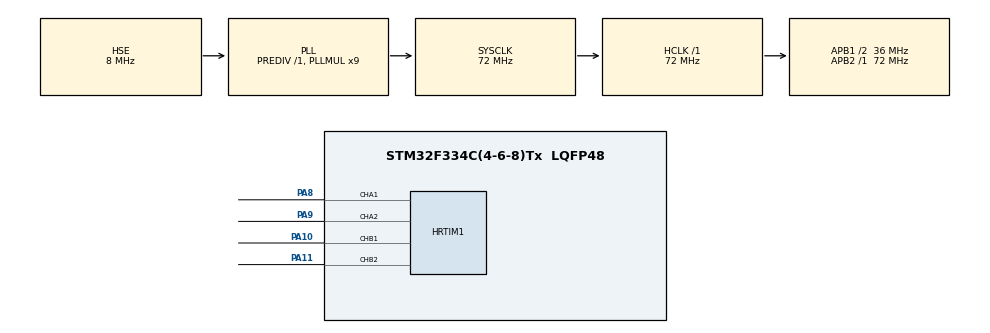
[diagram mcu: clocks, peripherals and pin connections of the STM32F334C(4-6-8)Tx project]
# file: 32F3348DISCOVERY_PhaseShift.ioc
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HRTIM1.CompareUnit1-MasterTimer=HRTIM_COMPAREUNIT_1
HRTIM1.CompareUnit1-Output_TA1TA2=HRTIM_COMPAREUNIT_1
HRTIM1.CompareUnit1-Output_TB1TB2=HRTIM_COMPAREUNIT_1
HRTIM1.CompareUnit2-MasterTimer=__NULL
HRTIM1.CompareUnit2-Output_TA1TA2=__NULL
HRTIM1.CompareUnit2-Output_TB1TB2=__NULL
HRTIM1.CompareUnit3-MasterTimer=__NULL
HRTIM1.CompareUnit4-MasterTimer=__NULL
HRTIM1.CompareValue1-MasterTimer=2880
HRTIM1.CompareValue2-MasterTimer=0xA000/5*2
HRTIM1.CompareValue3-MasterTimer=0xA000/5*3
HRTIM1.CompareValue4-MasterTimer=0xA000/5*4
HRTIM1.DeadTimeInsertion-Output_TA1TA2=HRTIM_TIMDEADTIMEINSERTION_ENABLED
HRTIM1.DeadTimeInsertion-Output_TB1TB2=HRTIM_TIMDEADTIMEINSERTION_ENABLED
HRTIM1.FallingValue-Output_TA1TA2=300
HRTIM1.FallingValue-Output_TB1TB2=300
HRTIM1.HalfModeEnable-Output_TA1TA2=HRTIM_HALFMODE_ENABLED
HRTIM1.HalfModeEnable-Output_TB1TB2=HRTIM_HALFMODE_ENABLED
HRTIM1.InterruptRequests1_Master=HRTIM_MASTER_IT_MREP
HRTIM1.ModeTimeBase-Output_TA1TA2=HRTIM_MODE_SINGLESHOT_RETRIGGERABLE
HRTIM1.ModeTimeBase-Output_TB1TB2=HRTIM_MODE_SINGLESHOT_RETRIGGERABLE
HRTIM1.NumberInterruptRequests_Master-MasterTimer=0
HRTIM1.NumberResetSource1-Output_TA1TA2=1
HRTIM1.NumberResetSource1-Output_TB1TB2=1
HRTIM1.NumberResetTrigger-Output_TA1TA2=1
HRTIM1.NumberResetTrigger-Output_TB1TB2=1
HRTIM1.NumberSetSource1-Output_TA1TA2=1
HRTIM1.NumberSetSource1-Output_TB1TB2=1
HRTIM1.NumberUpdateTrigger-Output_TA1TA2=0
HRTIM1.NumberUpdateTrigger-Output_TB1TB2=0
HRTIM1.Periode_MASTER=28800
HRTIM1.Periode_TA=28800
HRTIM1.Periode_TB=28800
HRTIM1.PreloadEnable-MasterTimer=HRTIM_PRELOAD_ENABLED
HRTIM1.PreloadEnable-Output_TA1TA2=HRTIM_PRELOAD_ENABLED
HRTIM1.PrescalerRatio_MASTER=HRTIM_PRESCALERRATIO_MUL16
HRTIM1.PrescalerRatio_TA=HRTIM_PRESCALERRATIO_MUL16
HRTIM1.PrescalerRatio_TB=HRTIM_PRESCALERRATIO_MUL16
HRTIM1.RepetitionCounter-MasterTimer=0
HRTIM1.RepetitionCounter-Output_TA1TA2=0
HRTIM1.RepetitionUpdate-MasterTimer=HRTIM_UPDATEONREPETITION_ENABLED
HRTIM1.RepetitionUpdate-Output_TA1TA2=HRTIM_UPDATEONREPETITION_DISABLED
HRTIM1.RepetitionUpdate-Output_TB1TB2=HRTIM_UPDATEONREPETITION_DISABLED
HRTIM1.ResetOutput1_Source1-Output_TA1TA2=HRTIM_OUTPUTRESET_TIMCMP1
HRTIM1.ResetOutput1_Source1-Output_TB1TB2=HRTIM_OUTPUTRESET_TIMCMP1
HRTIM1.ResetTrigger1-Output_TA1TA2=HRTIM_TIMRESETTRIGGER_MASTER_PER
HRTIM1.ResetTrigger1-Output_TB1TB2=HRTIM_TIMRESETTRIGGER_MASTER_CMP1
HRTIM1.ResetUpdate-Output_TA1TA2=HRTIM_TIMUPDATEONRESET_ENABLED
HRTIM1.ResetUpdate-Output_TB1TB2=HRTIM_TIMUPDATEONRESET_ENABLED
HRTIM1.RisingValue-Output_TA1TA2=300
HRTIM1.RisingValue-Output_TB1TB2=300
HRTIM1.SetOutput1_Source1-Output_TA1TA2=HRTIM_OUTPUTSET_TIMPER
HRTIM1.SetOutput1_Source1-Output_TB1TB2=HRTIM_OUTPUTSET_MASTERCMP1
HRTIM1.UpdateTrigger1-Output_TA1TA2=HRTIM_TIMUPDATETRIGGER_MASTER
HRTIM1.UpdateTrigger1-Output_TB1TB2=HRTIM_TIMUPDATETRIGGER_MASTER
Mcu.Family=STM32F3
Mcu.Name=STM32F334C(4-6-8)Tx
Mcu.Package=LQFP48
NVIC.PriorityGroup=NVIC_PRIORITYGROUP_0
PA10.Mode=Output_TB1TB2
PA10.Signal=HRTIM1_CHB1
PA11.Mode=Output_TB1TB2
PA11.Signal=HRTIM1_CHB2
PA13.Mode=Serial_Wire
PA13.Signal=SYS_JTMS-SWDIO
PA14.Mode=Serial_Wire
PA14.Signal=SYS_JTCK-SWCLK
PA8.Mode=Output_TA1TA2
PA8.Signal=HRTIM1_CHA1
PA9.Mode=Output_TA1TA2
PA9.Signal=HRTIM1_CHA2
PF0\ /\ OSC_IN.Mode=HSE-External-Clock-Source
PF0\ /\ OSC_IN.Signal=RCC_OSC_IN
ProjectManager.HeapSize=0x200
ProjectManager.StackSize=0x400
ProjectManager.TargetToolchain=STM32CubeIDE
RCC.AHBFreq_Value=72000000
RCC.APB1CLKDivider=RCC_HCLK_DIV2
RCC.APB1Freq_Value=36000000
RCC.APB1TimFreq_Value=72000000
RCC.APB2Freq_Value=72000000
RCC.APB2TimFreq_Value=72000000
RCC.CortexFreq_Value=72000000
RCC.HCLKFreq_Value=72000000
RCC.HRTIMSelection=RCC_HRTIM1CLK_PLLCLK
RCC.HSE_VALUE=8000000
RCC.HSI_VALUE=8000000
RCC.LSE_VALUE=32768
RCC.PLLMUL=RCC_PLL_MUL9
RCC.PLLSourceVirtual=RCC_PLLSOURCE_HSE
RCC.SYSCLKFreq_VALUE=72000000
RCC.SYSCLKSourceVirtual=RCC_SYSCLKSOURCE_PLLCLK
VP_HRTIM1_VS_hrtimMasterTimerNoOutput.Mode=MasterTimer
board=STM32F3348-DISCO

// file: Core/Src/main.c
/* USER CODE BEGIN Header */
/**
  ******************************************************************************
  * @file           : main.c
  * @brief          : Main program body
  ******************************************************************************
  * @attention
  *
  * <h2><center>&copy; Copyright (c) 2019 STMicroelectronics.
  * All rights reserved.</center></h2>
  *
  * This software component is licensed by ST under BSD 3-Clause license,
  * the "License"; You may not use this file except in compliance with the
  * License. You may obtain a copy of the License at:
  *                        opensource.org/licenses/BSD-3-Clause
  *
  ******************************************************************************
  */
/* USER CODE END Header */

#include "main.h"

HRTIM_HandleTypeDef hhrtim1;

void SystemClock_Config(void);
static void MX_GPIO_Init(void);
static void MX_HRTIM1_Init(void);
/* USER CODE BEGIN PFP */

static void HRTIM1_Start_Output(void);

/* USER CODE END PFP */

int main(void)
{

  /* MCU Configuration--------------------------------------------------------*/

  /* Reset of all peripherals, Initializes the Flash interface and the Systick. */
  HAL_Init();

  /* Configure the system clock */
  SystemClock_Config();

  /* Initialize all configured peripherals */
  MX_GPIO_Init();
  MX_HRTIM1_Init();
  /* USER CODE BEGIN 2 */

  HRTIM1_Start_Output();

  /* USER CODE END 2 */

  /* Infinite loop */
  while (1)
  {

  }
}

void SystemClock_Config(void)
{
  RCC_OscInitTypeDef RCC_OscInitStruct = {0};
  RCC_ClkInitTypeDef RCC_ClkInitStruct = {0};
  RCC_PeriphCLKInitTypeDef PeriphClkInit = {0};

  /** Initializes the CPU, AHB and APB busses clocks
  */
  RCC_OscInitStruct.OscillatorType = RCC_OSCILLATORTYPE_HSE;
  RCC_OscInitStruct.HSEState = RCC_HSE_BYPASS;
  RCC_OscInitStruct.HSEPredivValue = RCC_HSE_PREDIV_DIV1;
  RCC_OscInitStruct.HSIState = RCC_HSI_ON;
  RCC_OscInitStruct.PLL.PLLState = RCC_PLL_ON;
  RCC_OscInitStruct.PLL.PLLSource = RCC_PLLSOURCE_HSE;
  RCC_OscInitStruct.PLL.PLLMUL = RCC_PLL_MUL9;
  if (HAL_RCC_OscConfig(&RCC_OscInitStruct) != HAL_OK)
  {
    Error_Handler();
  }
  /** Initializes the CPU, AHB and APB busses clocks
  */
  RCC_ClkInitStruct.ClockType = RCC_CLOCKTYPE_HCLK|RCC_CLOCKTYPE_SYSCLK
                              |RCC_CLOCKTYPE_PCLK1|RCC_CLOCKTYPE_PCLK2;
  RCC_ClkInitStruct.SYSCLKSource = RCC_SYSCLKSOURCE_PLLCLK;
  RCC_ClkInitStruct.AHBCLKDivider = RCC_SYSCLK_DIV1;
  RCC_ClkInitStruct.APB1CLKDivider = RCC_HCLK_DIV2;
  RCC_ClkInitStruct.APB2CLKDivider = RCC_HCLK_DIV1;

  if (HAL_RCC_ClockConfig(&RCC_ClkInitStruct, FLASH_LATENCY_2) != HAL_OK)
  {
    Error_Handler();
  }
  PeriphClkInit.PeriphClockSelection = RCC_PERIPHCLK_HRTIM1;
  PeriphClkInit.Hrtim1ClockSelection = RCC_HRTIM1CLK_PLLCLK;
  if (HAL_RCCEx_PeriphCLKConfig(&PeriphClkInit) != HAL_OK)
  {
    Error_Handler();
  }
}

static void MX_HRTIM1_Init(void)
{

  HRTIM_TimeBaseCfgTypeDef pTimeBaseCfg = {0};
  HRTIM_TimerCfgTypeDef pTimerCfg = {0};
  HRTIM_CompareCfgTypeDef pCompareCfg = {0};
  HRTIM_DeadTimeCfgTypeDef pDeadTimeCfg = {0};
  HRTIM_OutputCfgTypeDef pOutputCfg = {0};

  hhrtim1.Instance = HRTIM1;
  hhrtim1.Init.HRTIMInterruptResquests = HRTIM_IT_NONE;
  hhrtim1.Init.SyncOptions = HRTIM_SYNCOPTION_NONE;
  if (HAL_HRTIM_Init(&hhrtim1) != HAL_OK)
  {
    Error_Handler();
  }
  if (HAL_HRTIM_DLLCalibrationStart(&hhrtim1, HRTIM_CALIBRATIONRATE_14) != HAL_OK)
  {
    Error_Handler();
  }
  if (HAL_HRTIM_PollForDLLCalibration(&hhrtim1, 10) != HAL_OK)
  {
    Error_Handler();
  }
  pTimeBaseCfg.Period = 28800;
  pTimeBaseCfg.RepetitionCounter = 0;
  pTimeBaseCfg.PrescalerRatio = HRTIM_PRESCALERRATIO_MUL16;
  pTimeBaseCfg.Mode = HRTIM_MODE_CONTINUOUS;
  if (HAL_HRTIM_TimeBaseConfig(&hhrtim1, HRTIM_TIMERINDEX_MASTER, &pTimeBaseCfg) != HAL_OK)
  {
    Error_Handler();
  }
  pTimerCfg.InterruptRequests = HRTIM_MASTER_IT_NONE;
  pTimerCfg.DMARequests = HRTIM_MASTER_DMA_NONE;
  pTimerCfg.DMASrcAddress = 0x0000;
  pTimerCfg.DMADstAddress = 0x0000;
  pTimerCfg.DMASize = 0x1;
  pTimerCfg.HalfModeEnable = HRTIM_HALFMODE_DISABLED;
  pTimerCfg.StartOnSync = HRTIM_SYNCSTART_DISABLED;
  pTimerCfg.ResetOnSync = HRTIM_SYNCRESET_DISABLED;
  pTimerCfg.DACSynchro = HRTIM_DACSYNC_NONE;
  pTimerCfg.PreloadEnable = HRTIM_PRELOAD_ENABLED;
  pTimerCfg.UpdateGating = HRTIM_UPDATEGATING_INDEPENDENT;
  pTimerCfg.BurstMode = HRTIM_TIMERBURSTMODE_MAINTAINCLOCK;
  pTimerCfg.RepetitionUpdate = HRTIM_UPDATEONREPETITION_ENABLED;
  if (HAL_HRTIM_WaveformTimerConfig(&hhrtim1, HRTIM_TIMERINDEX_MASTER, &pTimerCfg) != HAL_OK)
  {
    Error_Handler();
  }
  pCompareCfg.CompareValue = 2880;
  if (HAL_HRTIM_WaveformCompareConfig(&hhrtim1, HRTIM_TIMERINDEX_MASTER, HRTIM_COMPAREUNIT_1, &pCompareCfg) != HAL_OK)
  {
    Error_Handler();
  }
  pTimeBaseCfg.Mode = HRTIM_MODE_SINGLESHOT_RETRIGGERABLE;
  if (HAL_HRTIM_TimeBaseConfig(&hhrtim1, HRTIM_TIMERINDEX_TIMER_A, &pTimeBaseCfg) != HAL_OK)
  {
    Error_Handler();
  }
  pTimerCfg.InterruptRequests = HRTIM_TIM_IT_NONE;
  pTimerCfg.DMARequests = HRTIM_TIM_DMA_NONE;
  pTimerCfg.DMASrcAddress = 0x0000;
  pTimerCfg.DMADstAddress = 0x0000;
  pTimerCfg.DMASize = 0x1;
  pTimerCfg.HalfModeEnable = HRTIM_HALFMODE_ENABLED;
  pTimerCfg.RepetitionUpdate = HRTIM_UPDATEONREPETITION_DISABLED;
  pTimerCfg.PushPull = HRTIM_TIMPUSHPULLMODE_DISABLED;
  pTimerCfg.FaultEnable = HRTIM_TIMFAULTENABLE_NONE;
  pTimerCfg.FaultLock = HRTIM_TIMFAULTLOCK_READWRITE;
  pTimerCfg.DeadTimeInsertion = HRTIM_TIMDEADTIMEINSERTION_ENABLED;
  pTimerCfg.DelayedProtectionMode = HRTIM_TIMER_A_B_C_DELAYEDPROTECTION_DISABLED;
  pTimerCfg.UpdateTrigger = HRTIM_TIMUPDATETRIGGER_NONE;
  pTimerCfg.ResetTrigger = HRTIM_TIMRESETTRIGGER_MASTER_PER;
  pTimerCfg.ResetUpdate = HRTIM_TIMUPDATEONRESET_ENABLED;
  if (HAL_HRTIM_WaveformTimerConfig(&hhrtim1, HRTIM_TIMERINDEX_TIMER_A, &pTimerCfg) != HAL_OK)
  {
    Error_Handler();
  }
  pTimerCfg.DMASrcAddress = 0x0000;
  pTimerCfg.DMADstAddress = 0x0000;
  pTimerCfg.DMASize = 0x1;
  pTimerCfg.PreloadEnable = HRTIM_PRELOAD_DISABLED;
  pTimerCfg.ResetTrigger = HRTIM_TIMRESETTRIGGER_MASTER_CMP1;
  if (HAL_HRTIM_WaveformTimerConfig(&hhrtim1, HRTIM_TIMERINDEX_TIMER_B, &pTimerCfg) != HAL_OK)
  {
    Error_Handler();
  }
  pDeadTimeCfg.Prescaler = HRTIM_TIMDEADTIME_PRESCALERRATIO_MUL8;
  pDeadTimeCfg.RisingValue = 300;
  pDeadTimeCfg.RisingSign = HRTIM_TIMDEADTIME_RISINGSIGN_POSITIVE;
  pDeadTimeCfg.RisingLock = HRTIM_TIMDEADTIME_RISINGLOCK_WRITE;
  pDeadTimeCfg.RisingSignLock = HRTIM_TIMDEADTIME_RISINGSIGNLOCK_WRITE;
  pDeadTimeCfg.FallingValue = 300;
  pDeadTimeCfg.FallingSign = HRTIM_TIMDEADTIME_FALLINGSIGN_POSITIVE;
  pDeadTimeCfg.FallingLock = HRTIM_TIMDEADTIME_FALLINGLOCK_WRITE;
  pDeadTimeCfg.FallingSignLock = HRTIM_TIMDEADTIME_FALLINGSIGNLOCK_WRITE;
  if (HAL_HRTIM_DeadTimeConfig(&hhrtim1, HRTIM_TIMERINDEX_TIMER_A, &pDeadTimeCfg) != HAL_OK)
  {
    Error_Handler();
  }
  if (HAL_HRTIM_DeadTimeConfig(&hhrtim1, HRTIM_TIMERINDEX_TIMER_B, &pDeadTimeCfg) != HAL_OK)
  {
    Error_Handler();
  }
  pOutputCfg.Polarity = HRTIM_OUTPUTPOLARITY_HIGH;
  pOutputCfg.SetSource = HRTIM_OUTPUTSET_TIMPER;
  pOutputCfg.ResetSource = HRTIM_OUTPUTRESET_TIMCMP1;
  pOutputCfg.IdleMode = HRTIM_OUTPUTIDLEMODE_NONE;
  pOutputCfg.IdleLevel = HRTIM_OUTPUTIDLELEVEL_INACTIVE;
  pOutputCfg.FaultLevel = HRTIM_OUTPUTFAULTLEVEL_NONE;
  pOutputCfg.ChopperModeEnable = HRTIM_OUTPUTCHOPPERMODE_DISABLED;
  pOutputCfg.BurstModeEntryDelayed = HRTIM_OUTPUTBURSTMODEENTRY_REGULAR;
  if (HAL_HRTIM_WaveformOutputConfig(&hhrtim1, HRTIM_TIMERINDEX_TIMER_A, HRTIM_OUTPUT_TA1, &pOutputCfg) != HAL_OK)
  {
    Error_Handler();
  }
  pOutputCfg.SetSource = HRTIM_OUTPUTSET_MASTERCMP1;
  if (HAL_HRTIM_WaveformOutputConfig(&hhrtim1, HRTIM_TIMERINDEX_TIMER_B, HRTIM_OUTPUT_TB1, &pOutputCfg) != HAL_OK)
  {
    Error_Handler();
  }
  pOutputCfg.SetSource = HRTIM_OUTPUTSET_NONE;
  pOutputCfg.ResetSource = HRTIM_OUTPUTRESET_NONE;
  if (HAL_HRTIM_WaveformOutputConfig(&hhrtim1, HRTIM_TIMERINDEX_TIMER_A, HRTIM_OUTPUT_TA2, &pOutputCfg) != HAL_OK)
  {
    Error_Handler();
  }
  if (HAL_HRTIM_WaveformOutputConfig(&hhrtim1, HRTIM_TIMERINDEX_TIMER_B, HRTIM_OUTPUT_TB2, &pOutputCfg) != HAL_OK)
  {
    Error_Handler();
  }
  pTimeBaseCfg.RepetitionCounter = 0x00;
  if (HAL_HRTIM_TimeBaseConfig(&hhrtim1, HRTIM_TIMERINDEX_TIMER_B, &pTimeBaseCfg) != HAL_OK)
  {
    Error_Handler();
  }
  HAL_HRTIM_MspPostInit(&hhrtim1);

}

static void MX_GPIO_Init(void)
{

  /* GPIO Ports Clock Enable */
  __HAL_RCC_GPIOF_CLK_ENABLE();
  __HAL_RCC_GPIOA_CLK_ENABLE();

}

/* USER CODE BEGIN 4 */

static void HRTIM1_Start_Output(void)
{
	hhrtim1.Instance = HRTIM1;

	HAL_HRTIM_WaveformOutputStart(&hhrtim1, HRTIM_OUTPUT_TA1 | HRTIM_OUTPUT_TA2 | HRTIM_OUTPUT_TB1 | HRTIM_OUTPUT_TB2);
	HAL_HRTIM_WaveformCountStart_IT(&hhrtim1, HRTIM_TIMERID_MASTER | HRTIM_TIMERID_TIMER_A | HRTIM_TIMERID_TIMER_B);
}

/* USER CODE END 4 */

void Error_Handler(void)
{
}

/************************ (C) COPYRIGHT STMicroelectronics *****END OF FILE****/
